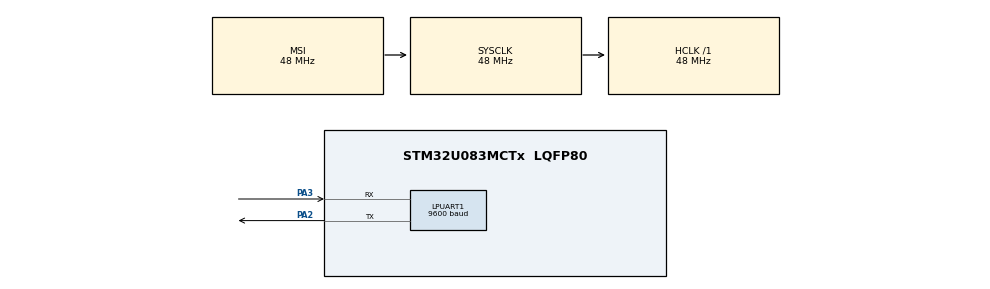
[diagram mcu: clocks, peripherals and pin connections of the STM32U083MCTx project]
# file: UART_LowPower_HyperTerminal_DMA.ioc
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Dma.LPUART1_RX.1.Direction=DMA_PERIPH_TO_MEMORY
Dma.LPUART1_RX.1.EventEnable=DISABLE
Dma.LPUART1_RX.1.Instance=DMA1_Channel2
Dma.LPUART1_RX.1.MemDataAlignment=DMA_MDATAALIGN_BYTE
Dma.LPUART1_RX.1.MemInc=DMA_MINC_ENABLE
Dma.LPUART1_RX.1.Mode=DMA_NORMAL
Dma.LPUART1_RX.1.PeriphDataAlignment=DMA_PDATAALIGN_BYTE
Dma.LPUART1_RX.1.PeriphInc=DMA_PINC_DISABLE
Dma.LPUART1_RX.1.Polarity=HAL_DMAMUX_REQ_GEN_RISING
Dma.LPUART1_RX.1.Priority=DMA_PRIORITY_HIGH
Dma.LPUART1_RX.1.RequestNumber=1
Dma.LPUART1_RX.1.SignalID=NONE
Dma.LPUART1_RX.1.SyncEnable=DISABLE
Dma.LPUART1_RX.1.SyncPolarity=HAL_DMAMUX_SYNC_NO_EVENT
Dma.LPUART1_RX.1.SyncRequestNumber=1
Dma.LPUART1_RX.1.SyncSignalID=NONE
Dma.LPUART1_TX.0.Direction=DMA_MEMORY_TO_PERIPH
Dma.LPUART1_TX.0.EventEnable=DISABLE
Dma.LPUART1_TX.0.Instance=DMA1_Channel1
Dma.LPUART1_TX.0.MemDataAlignment=DMA_MDATAALIGN_BYTE
Dma.LPUART1_TX.0.MemInc=DMA_MINC_ENABLE
Dma.LPUART1_TX.0.Mode=DMA_NORMAL
Dma.LPUART1_TX.0.PeriphDataAlignment=DMA_PDATAALIGN_BYTE
Dma.LPUART1_TX.0.PeriphInc=DMA_PINC_DISABLE
Dma.LPUART1_TX.0.Polarity=HAL_DMAMUX_REQ_GEN_RISING
Dma.LPUART1_TX.0.Priority=DMA_PRIORITY_LOW
Dma.LPUART1_TX.0.RequestNumber=1
Dma.LPUART1_TX.0.SignalID=NONE
Dma.LPUART1_TX.0.SyncEnable=DISABLE
Dma.LPUART1_TX.0.SyncPolarity=HAL_DMAMUX_SYNC_NO_EVENT
Dma.LPUART1_TX.0.SyncRequestNumber=1
Dma.LPUART1_TX.0.SyncSignalID=NONE
Dma.Request0=LPUART1_TX
Dma.Request1=LPUART1_RX
LPUART1.BaudRate=9600
LPUART1.DMADisableonRxErrorParam=UART_ADVFEATURE_DMA_ENABLEONRXERROR
LPUART1.DataInvertParam=UART_ADVFEATURE_DATAINV_DISABLE
LPUART1.MSBFirstParam=UART_ADVFEATURE_MSBFIRST_DISABLE
LPUART1.Mode=UART_MODE_TX_RX
LPUART1.OneBitSampling=UART_ONE_BIT_SAMPLE_DISABLE
LPUART1.OverrunDisableParam=UART_ADVFEATURE_OVERRUN_ENABLE
LPUART1.Parity=UART_PARITY_ODD
LPUART1.RxPinLevelInvertParam=UART_ADVFEATURE_RXINV_DISABLE
LPUART1.StopBits=UART_STOPBITS_1
LPUART1.SwapParam=UART_ADVFEATURE_SWAP_DISABLE
LPUART1.TxPinLevelInvertParam=UART_ADVFEATURE_TXINV_DISABLE
LPUART1.WordLength=UART_WORDLENGTH_8B
Mcu.Family=STM32U0
Mcu.Name=STM32U083MCTx
Mcu.Package=LQFP80
NVIC.DMA1_Channel1_IRQn=true\:0\:0\:false\:false\:true\:true\:true\:true
NVIC.DMA1_Channel2_3_IRQn=true\:0\:0\:false\:false\:true\:true\:true\:true
NVIC.PriorityGroup=NVIC_PRIORITYGROUP_2
NVIC.USART3_LPUART1_IRQn=true\:0\:0\:false\:false\:true\:true\:true\:true
PA2.GPIO_PuPd=GPIO_PULLUP
PA2.Mode=Asynchronous
PA2.Signal=LPUART1_TX
PA3.GPIO_PuPd=GPIO_PULLUP
PA3.Mode=Asynchronous
PA3.Signal=LPUART1_RX
ProjectManager.HeapSize=0x200
ProjectManager.StackSize=0x400
ProjectManager.TargetToolchain=EWARM V9.20
RCC.ADCFreq_Value=48000000
RCC.AHBFreq_Value=48000000
RCC.CortexFreq_Value=48000000
RCC.HCLKFreq_Value=48000000
RCC.HSE_VALUE=4000000
RCC.HSI48_VALUE=48000000
RCC.HSI_VALUE=16000000
RCC.LPUART1CLockSelection=RCC_LPUART1CLKSOURCE_HSI
RCC.LSE_VALUE=32768
RCC.MSIClockRangeVal=RCC_MSIRANGE_11
RCC.MSI_VALUE=48000000
RCC.PLLM=RCC_PLLM_DIV8
RCC.PLLN=8
RCC.PLLSourceVirtual=RCC_PLLSOURCE_MSI
RCC.SYSCLKFreq_VALUE=48000000
RCC.SYSCLKSource=RCC_SYSCLKSOURCE_MSI
RCC.USBFreq_Value=48000000
RCC.VCOOutputFreq_Value=48000000
VP_PWR_VS_SECSignals.Mode=Security/Privilege
board=custom

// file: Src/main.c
/* USER CODE BEGIN Header */
/**
  ******************************************************************************
  * @file           : main.c
  * @brief          : Main program body
  ******************************************************************************
  * @attention
  *
  * Copyright (c) 2023 STMicroelectronics.
  * All rights reserved.
  *
  * This software is licensed under terms that can be found in the LICENSE file
  * in the root directory of this software component.
  * If no LICENSE file comes with this software, it is provided AS-IS.
  *
  ******************************************************************************
  */
/* USER CODE END Header */
#include "main.h"

/* USER CODE BEGIN Includes */
#include "stm32u083c_discovery.h"
/* USER CODE END Includes */

UART_HandleTypeDef hlpuart1;
DMA_HandleTypeDef hdma_lpuart1_tx;
DMA_HandleTypeDef hdma_lpuart1_rx;

/* USER CODE BEGIN PV */
/* Private variables ---------------------------------------------------------*/
/* Buffer used for transmission */
uint8_t aTxBuffer[] = "\n\r ****UART-Hyperterminal communication based on DMA****\n\r Enter 10 characters using keyboard :\n\r";

/* Buffer used for reception */
uint8_t aRxBuffer[RXBUFFERSIZE];
/* USER CODE END PV */

void SystemClock_Config(void);
static void MX_GPIO_Init(void);
static void MX_DMA_Init(void);
static void MX_LPUART1_UART_Init(void);

int main(void)
{
  /* USER CODE BEGIN 1 */
  /* STM32U0xx HAL library initialization:
       - Configure the Flash prefetch
       - Systick timer is configured by default as source of time base, but user
         can eventually implement his proper time base source (a general purpose
         timer for example or other time source), keeping in mind that Time base
         duration should be kept 1ms since PPP_TIMEOUT_VALUEs are defined and
         handled in milliseconds basis.
       - Set NVIC Group Priority to 4
       - Low Level Initialization
     */
  /* USER CODE END 1 */

  /* MCU Configuration--------------------------------------------------------*/

  /* Reset of all peripherals, Initializes the Flash interface and the Systick. */
  HAL_Init();

  /* Configure the system clock */
  SystemClock_Config();

  /* Initialize all configured peripherals */
  MX_GPIO_Init();
  MX_DMA_Init();
  MX_LPUART1_UART_Init();
  /* USER CODE BEGIN 2 */
  /* Configure LED3, LED4 and LED5 */
  BSP_LED_Init(LED3);
  BSP_LED_Init(LED4);
  BSP_LED_Init(LED5);

  /*##-1- Start the transmission process #####################################*/
  /* User start transmission data through "TxBuffer" buffer */
  if (HAL_UART_Transmit_DMA(&hlpuart1, (uint8_t *)aTxBuffer, TXBUFFERSIZE) != HAL_OK)
  {
    /* Transfer error in transmission process */
    Error_Handler();
  }

  /*##-2- Put UART peripheral in reception process ###########################*/
  /* Any data received will be stored in "RxBuffer" buffer : the number max of
     data received is 10 */
  if (HAL_UART_Receive_DMA(&hlpuart1, (uint8_t *)aRxBuffer, RXBUFFERSIZE) != HAL_OK)
  {
    /* Transfer error in reception process */
    Error_Handler();
  }

  /*##-3- Wait for the end of the transfer ###################################*/
  /*  Before starting a new communication transfer, you need to check the current
      state of the peripheral; if it's busy you need to wait for the end of current
      transfer before starting a new one.
      For simplicity reasons, this example is just waiting till the end of the
      transfer, but application may perform other tasks while transfer operation
      is ongoing. */
  while (HAL_UART_GetState(&hlpuart1) != HAL_UART_STATE_READY)
  {
  }

  /*##-4- Send the received Buffer ###########################################*/
  if (HAL_UART_Transmit_DMA(&hlpuart1, (uint8_t *)aRxBuffer, RXBUFFERSIZE) != HAL_OK)
  {
    /* Transfer error in transmission process */
    Error_Handler();
  }

  /*##-5- Wait for the end of the transfer ###################################*/
  /*  Before starting a new communication transfer, you need to check the current
      state of the peripheral; if it's busy you need to wait for the end of current
      transfer before starting a new one.
      For simplicity reasons, this example is just waiting till the end of the
      transfer, but application may perform other tasks while transfer operation
      is ongoing. */
  while (HAL_UART_GetState(&hlpuart1) != HAL_UART_STATE_READY)
  {
  }

  /* USER CODE END 2 */

  /* Infinite loop */
  while (1)
  {

  }
}

void SystemClock_Config(void)
{
  RCC_OscInitTypeDef RCC_OscInitStruct = {0};
  RCC_ClkInitTypeDef RCC_ClkInitStruct = {0};

  /** Configure the main internal regulator output voltage
  */
  HAL_PWREx_ControlVoltageScaling(PWR_REGULATOR_VOLTAGE_SCALE1);

  /** Initializes the RCC Oscillators according to the specified parameters
  * in the RCC_OscInitTypeDef structure.
  */
  RCC_OscInitStruct.OscillatorType = RCC_OSCILLATORTYPE_HSI|RCC_OSCILLATORTYPE_MSI;
  RCC_OscInitStruct.HSIState = RCC_HSI_ON;
  RCC_OscInitStruct.HSICalibrationValue = RCC_HSICALIBRATION_DEFAULT;
  RCC_OscInitStruct.MSIState = RCC_MSI_ON;
  RCC_OscInitStruct.MSICalibrationValue = RCC_MSICALIBRATION_DEFAULT;
  RCC_OscInitStruct.MSIClockRange = RCC_MSIRANGE_11;
  RCC_OscInitStruct.PLL.PLLState = RCC_PLL_NONE;
  if (HAL_RCC_OscConfig(&RCC_OscInitStruct) != HAL_OK)
  {
    Error_Handler();
  }

  /** Initializes the CPU, AHB and APB buses clocks
  */
  RCC_ClkInitStruct.ClockType = RCC_CLOCKTYPE_HCLK|RCC_CLOCKTYPE_SYSCLK
                              |RCC_CLOCKTYPE_PCLK1;
  RCC_ClkInitStruct.SYSCLKSource = RCC_SYSCLKSOURCE_MSI;
  RCC_ClkInitStruct.AHBCLKDivider = RCC_SYSCLK_DIV1;
  RCC_ClkInitStruct.APB1CLKDivider = RCC_HCLK_DIV1;

  if (HAL_RCC_ClockConfig(&RCC_ClkInitStruct, FLASH_LATENCY_1) != HAL_OK)
  {
    Error_Handler();
  }
}

static void MX_LPUART1_UART_Init(void)
{

  hlpuart1.Instance = LPUART1;
  hlpuart1.Init.BaudRate = 9600;
  hlpuart1.Init.WordLength = UART_WORDLENGTH_8B;
  hlpuart1.Init.StopBits = UART_STOPBITS_1;
  hlpuart1.Init.Parity = UART_PARITY_ODD;
  hlpuart1.Init.Mode = UART_MODE_TX_RX;
  hlpuart1.Init.HwFlowCtl = UART_HWCONTROL_NONE;
  hlpuart1.Init.OneBitSampling = UART_ONE_BIT_SAMPLE_DISABLE;
  hlpuart1.AdvancedInit.AdvFeatureInit = UART_ADVFEATURE_NO_INIT;
  hlpuart1.FifoMode = UART_FIFOMODE_DISABLE;
  if (HAL_UART_Init(&hlpuart1) != HAL_OK)
  {
    Error_Handler();
  }
  if (HAL_UARTEx_SetTxFifoThreshold(&hlpuart1, UART_TXFIFO_THRESHOLD_1_8) != HAL_OK)
  {
    Error_Handler();
  }
  if (HAL_UARTEx_SetRxFifoThreshold(&hlpuart1, UART_RXFIFO_THRESHOLD_1_8) != HAL_OK)
  {
    Error_Handler();
  }
  if (HAL_UARTEx_DisableFifoMode(&hlpuart1) != HAL_OK)
  {
    Error_Handler();
  }

}

static void MX_DMA_Init(void)
{

  /* DMA controller clock enable */
  __HAL_RCC_DMA1_CLK_ENABLE();

  /* DMA interrupt init */
  /* DMA1_Channel1_IRQn interrupt configuration */
  HAL_NVIC_SetPriority(DMA1_Channel1_IRQn, 0, 0);
  HAL_NVIC_EnableIRQ(DMA1_Channel1_IRQn);
  /* DMA1_Channel2_3_IRQn interrupt configuration */
  HAL_NVIC_SetPriority(DMA1_Channel2_3_IRQn, 0, 0);
  HAL_NVIC_EnableIRQ(DMA1_Channel2_3_IRQn);

}

static void MX_GPIO_Init(void)
{

  /* GPIO Ports Clock Enable */
  __HAL_RCC_GPIOA_CLK_ENABLE();

}

/* USER CODE BEGIN 4 */
/**
  * @brief  Tx Transfer completed callback
  * @param  huart: UART handle.
  * @note   This example shows a simple way to report end of DMA Tx transfer, and
  *         you can add your own implementation.
  * @retval None
  */
void HAL_UART_TxCpltCallback(UART_HandleTypeDef *huart)
{
  /* Turn LED1 on: Transfer in transmission process is correct */
  BSP_LED_On(LED3);
}

/**
  * @brief  Rx Transfer completed callback
  * @param  huart: UART handle
  * @note   This example shows a simple way to report end of DMA Rx transfer, and
  *         you can add your own implementation.
  * @retval None
  */
void HAL_UART_RxCpltCallback(UART_HandleTypeDef *huart)
{
  /* Turn LED4 on: Transfer in reception process is correct */
  BSP_LED_On(LED4);
}

/**
  * @brief  UART error callbacks
  * @param  huart: UART handle
  * @note   This example shows a simple way to report transfer error, and you can
  *         add your own implementation.
  * @retval None
  */
void HAL_UART_ErrorCallback(UART_HandleTypeDef *huart)
{
  /* Turn LED5 on: Transfer error in reception/transmission process */
  BSP_LED_On(LED5);
}
/* USER CODE END 4 */

void Error_Handler(void)
{
  __disable_irq();
  while (1)
  {
  }
}
